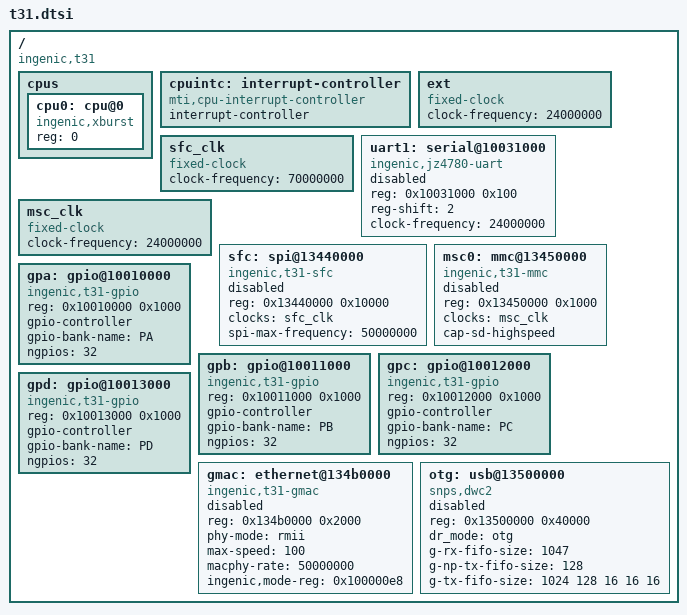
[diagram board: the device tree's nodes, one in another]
// SPDX-License-Identifier: GPL-2.0+

/ {
	#address-cells = <1>;
	#size-cells = <1>;
	compatible = "ingenic,t31";

	cpus {
		#address-cells = <1>;
		#size-cells = <0>;

		cpu0: cpu@0 {
			device_type = "cpu";
			compatible = "ingenic,xburst", "mips,mips32r2";
			reg = <0>;
		};
	};

	cpuintc: interrupt-controller {
		#address-cells = <0>;
		#interrupt-cells = <1>;
		interrupt-controller;
		compatible = "mti,cpu-interrupt-controller";
	};

	ext: ext {
		compatible = "fixed-clock";
		#clock-cells = <0>;
		clock-frequency = <24000000>;
	};

	/*
	 * SFC source clock. The SPL programs the SSI/SFC clock divider
	 * to 70 MHz before handing off to U-Boot proper, which inherits
	 * the running clock. Model it as a fixed-clock so the SFC driver
	 * can resolve its "clocks" phandle without a full CGU driver.
	 */
	sfc_clk: sfc_clk {
		compatible = "fixed-clock";
		#clock-cells = <0>;
		clock-frequency = <70000000>;
	};

	uart1: serial@10031000 {
		compatible = "ingenic,jz4780-uart";
		reg = <0x10031000 0x100>;
		reg-shift = <2>;
		clock-frequency = <24000000>;
		status = "disabled";
	};

	/*
	 * MSC functional clock. board_init() programs CPM_MSC0CDR so the
	 * MSC0 clock runs at 24 MHz (the rate jz_mmc assumes); model it as
	 * a fixed-clock so the node's "clocks" phandle resolves without a
	 * full CGU driver.
	 */
	msc_clk: msc_clk {
		compatible = "fixed-clock";
		#clock-cells = <0>;
		clock-frequency = <24000000>;
	};

	sfc: spi@13440000 {
		compatible = "ingenic,t31-sfc";
		reg = <0x13440000 0x10000>;
		#address-cells = <1>;
		#size-cells = <0>;
		clocks = <&sfc_clk>;
		spi-max-frequency = <50000000>;
		status = "disabled";
	};

	msc0: mmc@13450000 {
		compatible = "ingenic,t31-mmc";
		reg = <0x13450000 0x1000>;
		clocks = <&msc_clk>;
		clock-names = "mmc";
		cap-sd-highspeed;
		status = "disabled";
	};

	/*
	 * GPIO ports PA..PD. Always available (no board gating) so the
	 * gpio command can drive board-specific pins - e.g. an SD/MMC
	 * power-enable that varies per device and is not hardcoded.
	 */
	gpa: gpio@10010000 {
		compatible = "ingenic,t31-gpio";
		reg = <0x10010000 0x1000>;
		gpio-controller;
		#gpio-cells = <2>;
		gpio-bank-name = "PA";
		ngpios = <32>;
	};

	gpb: gpio@10011000 {
		compatible = "ingenic,t31-gpio";
		reg = <0x10011000 0x1000>;
		gpio-controller;
		#gpio-cells = <2>;
		gpio-bank-name = "PB";
		ngpios = <32>;
	};

	gpc: gpio@10012000 {
		compatible = "ingenic,t31-gpio";
		reg = <0x10012000 0x1000>;
		gpio-controller;
		#gpio-cells = <2>;
		gpio-bank-name = "PC";
		ngpios = <32>;
	};

	gpd: gpio@10013000 {
		compatible = "ingenic,t31-gpio";
		reg = <0x10013000 0x1000>;
		gpio-controller;
		#gpio-cells = <2>;
		gpio-bank-name = "PD";
		ngpios = <32>;
	};

	/*
	 * GMAC: Synopsys DesignWare MAC. ingenic,mode-reg is the CPM
	 * GMAC-PHY-control register (CPM 0xb0000000 + 0xe8) used to
	 * select the PHY interface and speed; the glue also ungates the
	 * GMAC clock and programs CPM_MACCDR for the MAC-PHY rate.
	 */
	gmac: ethernet@134b0000 {
		compatible = "ingenic,t31-gmac";
		reg = <0x134b0000 0x2000>;
		phy-mode = "rmii";
		max-speed = <100>;
		macphy-rate = <50000000>;
		ingenic,mode-reg = <0x100000e8>;
		status = "disabled";
	};

	/*
	 * DWC2 USB OTG. board_init() brings up the PHY/clock. The same
	 * node serves both the host driver (usb start -> USB ethernet,
	 * storage) and the gadget driver (dfu / ums for flashing).
	 */
	otg: usb@13500000 {
		compatible = "snps,dwc2";
		reg = <0x13500000 0x40000>;
		dr_mode = "otg";
		/*
		 * FIFO depths (32-bit words) from the mask ROM's working
		 * USB-device setup (bootrom: GRXFSIZ=0x417,
		 * GNPTXFSIZ depth=0x80, DIEPTXF1=0x400, DIEPTXF2=0x80) -
		 * it is a proven device on this exact DWC2. The previous
		 * generic values undersized the RX FIFO and corrupted
		 * EP0/descriptor transfers.
		 */
		g-rx-fifo-size = <1047>;
		g-np-tx-fifo-size = <128>;
		g-tx-fifo-size = <1024 128 16 16 16>;
		status = "disabled";
	};
};
